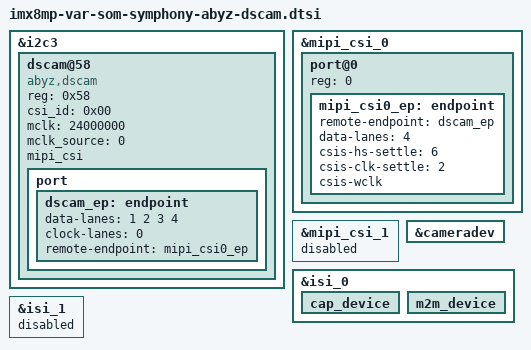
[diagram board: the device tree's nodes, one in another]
// SPDX-License-Identifier: (GPL-2.0+ OR MIT)
/*
 * Copyright 2019 NXP
 * Copyright 2020-2021 Variscite Ltd.
 */


&i2c3{


	/delete-node/ov5640_mipi@3c; 

	dscam@58{
		compatible="abyz,dscam";
		reg=<0x58>;
		csi_id=<0x00>;
		/* mipi_csi;*/
		mclk = <24000000>;
		mclk_source = <0>;
		mipi_csi;
		status = "okay";
	
		port{
			dscam_ep:endpoint{
				data-lanes = < 1 2 3 4>;
				clock-lanes = <0>;
				remote-endpoint = <&mipi_csi0_ep>;
			};
		};
	};


};

&mipi_csi_0 {
	#address-cells = <1>;
	#size-cells = <0>;
	status = "okay";

	port@0 {
		reg = <0>;
		mipi_csi0_ep: endpoint {

			remote-endpoint = <&dscam_ep>;

			data-lanes = <4>;
			csis-hs-settle = <6>;
			csis-clk-settle = <2>;
			csis-wclk;
		};
	};
};

&mipi_csi_1 {
	status = "disabled";
};

&cameradev {
	status = "okay";
};

&isi_0 {
	status = "okay";

	cap_device {
		status = "okay";
	};

	m2m_device {
		status = "okay";
	};
};

&isi_1 {
	status = "disabled";
};
